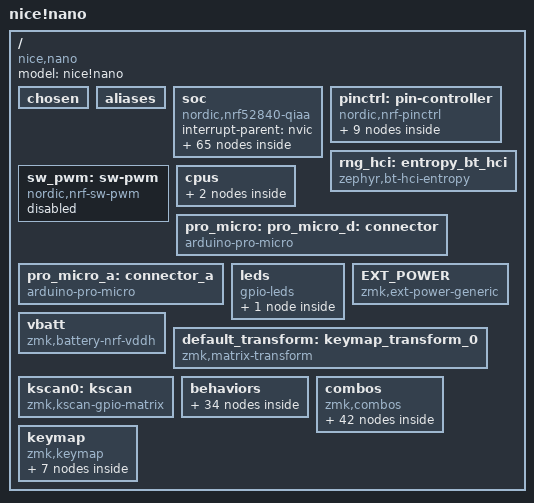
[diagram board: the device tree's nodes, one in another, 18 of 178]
/dts-v1/;

/ {
	#address-cells = < 0x1 >;
	#size-cells = < 0x1 >;
	model = "nice!nano";
	compatible = "nice,nano";
	chosen {
		zephyr,entropy = &rng;
		zephyr,flash-controller = &flash_controller;
		zephyr,code-partition = &code_partition;
		zephyr,sram = &sram0;
		zephyr,flash = &flash0;
		zephyr,console = &cdc_acm_uart;
		zmk,battery = &vbatt;
		zmk,matrix-transform = &default_transform;
		zmk,kscan = &kscan0;
	};
	aliases {
	};
	soc {
		#address-cells = < 0x1 >;
		#size-cells = < 0x1 >;
		compatible = "nordic,nrf52840-qiaa", "nordic,nrf52840", "nordic,nrf52", "simple-bus";
		interrupt-parent = < &nvic >;
		ranges;
		nvic: interrupt-controller@e000e100 {
			#address-cells = < 0x1 >;
			compatible = "arm,v7m-nvic";
			reg = < 0xe000e100 0xc00 >;
			interrupt-controller;
			#interrupt-cells = < 0x2 >;
			arm,num-irq-priority-bits = < 0x3 >;
			phandle = < 0x1 >;
		};
		systick: timer@e000e010 {
			compatible = "arm,armv7m-systick";
			reg = < 0xe000e010 0x10 >;
			status = "disabled";
		};
		ficr: ficr@10000000 {
			compatible = "nordic,nrf-ficr";
			reg = < 0x10000000 0x1000 >;
			status = "okay";
		};
		uicr: uicr@10001000 {
			compatible = "nordic,nrf-uicr";
			reg = < 0x10001000 0x1000 >;
			status = "okay";
		};
		sram0: memory@20000000 {
			compatible = "mmio-sram";
			reg = < 0x20000000 0x40000 >;
		};
		clock: clock@40000000 {
			compatible = "nordic,nrf-clock";
			reg = < 0x40000000 0x1000 >;
			interrupts = < 0x0 0x1 >;
			status = "okay";
		};
		power: power@40000000 {
			compatible = "nordic,nrf-power";
			reg = < 0x40000000 0x1000 >;
			interrupts = < 0x0 0x1 >;
			status = "okay";
			#address-cells = < 0x1 >;
			#size-cells = < 0x1 >;
			gpregret1: gpregret1@4000051c {
				#address-cells = < 0x1 >;
				#size-cells = < 0x1 >;
				compatible = "nordic,nrf-gpregret";
				reg = < 0x4000051c 0x1 >;
				status = "okay";
			};
			gpregret2: gpregret2@40000520 {
				#address-cells = < 0x1 >;
				#size-cells = < 0x1 >;
				compatible = "nordic,nrf-gpregret";
				reg = < 0x40000520 0x1 >;
				status = "okay";
			};
		};
		radio: radio@40001000 {
			compatible = "nordic,nrf-radio";
			reg = < 0x40001000 0x1000 >;
			interrupts = < 0x1 0x1 >;
			status = "okay";
			ieee802154-supported;
			ble-2mbps-supported;
			ble-coded-phy-supported;
			tx-high-power-supported;
			ieee802154: ieee802154 {
				compatible = "nordic,nrf-ieee802154";
				status = "disabled";
			};
		};
		uart0: pro_micro_serial: uart@40002000 {
			compatible = "nordic,nrf-uarte";
			reg = < 0x40002000 0x1000 >;
			interrupts = < 0x2 0x1 >;
			status = "disabled";
			current-speed = < 0x1c200 >;
			pinctrl-0 = < &uart0_default >;
			pinctrl-1 = < &uart0_sleep >;
			pinctrl-names = "default", "sleep";
		};
		i2c0: pro_micro_i2c: i2c@40003000 {
			compatible = "nordic,nrf-twi";
			#address-cells = < 0x1 >;
			#size-cells = < 0x0 >;
			reg = < 0x40003000 0x1000 >;
			clock-frequency = < 0x186a0 >;
			interrupts = < 0x3 0x1 >;
			easydma-maxcnt-bits = < 0x10 >;
			status = "disabled";
			pinctrl-0 = < &i2c0_default >;
			pinctrl-1 = < &i2c0_sleep >;
			pinctrl-names = "default", "sleep";
		};
		spi0: pro_micro_spi: spi@40003000 {
			compatible = "nordic,nrf-spim";
			#address-cells = < 0x1 >;
			#size-cells = < 0x0 >;
			reg = < 0x40003000 0x1000 >;
			interrupts = < 0x3 0x1 >;
			max-frequency = < 0x7a1200 >;
			easydma-maxcnt-bits = < 0x10 >;
			status = "disabled";
		};
		i2c1: i2c@40004000 {
			compatible = "nordic,nrf-twim";
			#address-cells = < 0x1 >;
			#size-cells = < 0x0 >;
			reg = < 0x40004000 0x1000 >;
			clock-frequency = < 0x186a0 >;
			interrupts = < 0x4 0x1 >;
			easydma-maxcnt-bits = < 0x10 >;
			status = "disabled";
		};
		spi1: spi@40004000 {
			compatible = "nordic,nrf-spim";
			#address-cells = < 0x1 >;
			#size-cells = < 0x0 >;
			reg = < 0x40004000 0x1000 >;
			interrupts = < 0x4 0x1 >;
			max-frequency = < 0x7a1200 >;
			easydma-maxcnt-bits = < 0x10 >;
			status = "disabled";
		};
		nfct: nfct@40005000 {
			compatible = "nordic,nrf-nfct";
			reg = < 0x40005000 0x1000 >;
			interrupts = < 0x5 0x1 >;
			status = "okay";
		};
		gpiote: gpiote@40006000 {
			compatible = "nordic,nrf-gpiote";
			reg = < 0x40006000 0x1000 >;
			interrupts = < 0x6 0x5 >;
			status = "okay";
		};
		adc: adc@40007000 {
			compatible = "nordic,nrf-saadc";
			reg = < 0x40007000 0x1000 >;
			interrupts = < 0x7 0x1 >;
			status = "okay";
			#io-channel-cells = < 0x1 >;
		};
		timer0: timer@40008000 {
			compatible = "nordic,nrf-timer";
			status = "disabled";
			reg = < 0x40008000 0x1000 >;
			cc-num = < 0x4 >;
			max-bit-width = < 0x20 >;
			interrupts = < 0x8 0x1 >;
			prescaler = < 0x0 >;
		};
		timer1: timer@40009000 {
			compatible = "nordic,nrf-timer";
			status = "disabled";
			reg = < 0x40009000 0x1000 >;
			cc-num = < 0x4 >;
			max-bit-width = < 0x20 >;
			interrupts = < 0x9 0x1 >;
			prescaler = < 0x0 >;
			phandle = < 0x6 >;
		};
		timer2: timer@4000a000 {
			compatible = "nordic,nrf-timer";
			status = "disabled";
			reg = < 0x4000a000 0x1000 >;
			cc-num = < 0x4 >;
			max-bit-width = < 0x20 >;
			interrupts = < 0xa 0x1 >;
			prescaler = < 0x0 >;
		};
		rtc0: rtc@4000b000 {
			compatible = "nordic,nrf-rtc";
			reg = < 0x4000b000 0x1000 >;
			cc-num = < 0x3 >;
			interrupts = < 0xb 0x1 >;
			status = "disabled";
			clock-frequency = < 0x8000 >;
			prescaler = < 0x1 >;
		};
		temp: temp@4000c000 {
			compatible = "nordic,nrf-temp";
			reg = < 0x4000c000 0x1000 >;
			interrupts = < 0xc 0x1 >;
			status = "okay";
		};
		rng: random@4000d000 {
			compatible = "nordic,nrf-rng";
			reg = < 0x4000d000 0x1000 >;
			interrupts = < 0xd 0x1 >;
			status = "okay";
		};
		ecb: ecb@4000e000 {
			compatible = "nordic,nrf-ecb";
			reg = < 0x4000e000 0x1000 >;
			interrupts = < 0xe 0x1 >;
			status = "okay";
		};
		ccm: ccm@4000f000 {
			compatible = "nordic,nrf-ccm";
			reg = < 0x4000f000 0x1000 >;
			interrupts = < 0xf 0x1 >;
			length-field-length-8-bits;
			status = "okay";
		};
		wdt: wdt0: watchdog@40010000 {
			compatible = "nordic,nrf-wdt";
			reg = < 0x40010000 0x1000 >;
			interrupts = < 0x10 0x1 >;
			status = "okay";
		};
		rtc1: rtc@40011000 {
			compatible = "nordic,nrf-rtc";
			reg = < 0x40011000 0x1000 >;
			cc-num = < 0x4 >;
			interrupts = < 0x11 0x1 >;
			status = "disabled";
			clock-frequency = < 0x8000 >;
			prescaler = < 0x1 >;
		};
		qdec: qdec0: qdec@40012000 {
			compatible = "nordic,nrf-qdec";
			reg = < 0x40012000 0x1000 >;
			interrupts = < 0x12 0x1 >;
			status = "disabled";
		};
		comp: comparator@40013000 {
			compatible = "nordic,nrf-comp";
			reg = < 0x40013000 0x1000 >;
			interrupts = < 0x13 0x1 >;
			status = "disabled";
			#io-channel-cells = < 0x1 >;
		};
		egu0: swi0: egu@40014000 {
			compatible = "nordic,nrf-egu", "nordic,nrf-swi";
			reg = < 0x40014000 0x1000 >;
			interrupts = < 0x14 0x1 >;
			status = "okay";
		};
		egu1: swi1: egu@40015000 {
			compatible = "nordic,nrf-egu", "nordic,nrf-swi";
			reg = < 0x40015000 0x1000 >;
			interrupts = < 0x15 0x1 >;
			status = "okay";
		};
		egu2: swi2: egu@40016000 {
			compatible = "nordic,nrf-egu", "nordic,nrf-swi";
			reg = < 0x40016000 0x1000 >;
			interrupts = < 0x16 0x1 >;
			status = "okay";
		};
		egu3: swi3: egu@40017000 {
			compatible = "nordic,nrf-egu", "nordic,nrf-swi";
			reg = < 0x40017000 0x1000 >;
			interrupts = < 0x17 0x1 >;
			status = "okay";
		};
		egu4: swi4: egu@40018000 {
			compatible = "nordic,nrf-egu", "nordic,nrf-swi";
			reg = < 0x40018000 0x1000 >;
			interrupts = < 0x18 0x1 >;
			status = "okay";
		};
		egu5: swi5: egu@40019000 {
			compatible = "nordic,nrf-egu", "nordic,nrf-swi";
			reg = < 0x40019000 0x1000 >;
			interrupts = < 0x19 0x1 >;
			status = "okay";
		};
		timer3: timer@4001a000 {
			compatible = "nordic,nrf-timer";
			status = "disabled";
			reg = < 0x4001a000 0x1000 >;
			cc-num = < 0x6 >;
			max-bit-width = < 0x20 >;
			interrupts = < 0x1a 0x1 >;
			prescaler = < 0x0 >;
		};
		timer4: timer@4001b000 {
			compatible = "nordic,nrf-timer";
			status = "disabled";
			reg = < 0x4001b000 0x1000 >;
			cc-num = < 0x6 >;
			max-bit-width = < 0x20 >;
			interrupts = < 0x1b 0x1 >;
			prescaler = < 0x0 >;
		};
		pwm0: pwm@4001c000 {
			compatible = "nordic,nrf-pwm";
			reg = < 0x4001c000 0x1000 >;
			interrupts = < 0x1c 0x1 >;
			status = "disabled";
			#pwm-cells = < 0x3 >;
		};
		pdm0: pdm@4001d000 {
			compatible = "nordic,nrf-pdm";
			reg = < 0x4001d000 0x1000 >;
			interrupts = < 0x1d 0x1 >;
			status = "disabled";
		};
		acl: acl@4001e000 {
			compatible = "nordic,nrf-acl";
			reg = < 0x4001e000 0x1000 >;
			status = "okay";
		};
		flash_controller: flash-controller@4001e000 {
			compatible = "nordic,nrf52-flash-controller";
			reg = < 0x4001e000 0x1000 >;
			partial-erase;
			#address-cells = < 0x1 >;
			#size-cells = < 0x1 >;
			flash0: flash@0 {
				compatible = "soc-nv-flash";
				erase-block-size = < 0x1000 >;
				write-block-size = < 0x4 >;
				reg = < 0x0 0x100000 >;
				partitions {
					compatible = "fixed-partitions";
					#address-cells = < 0x1 >;
					#size-cells = < 0x1 >;
					sd_partition: partition@0 {
						reg = < 0x0 0x26000 >;
					};
					code_partition: partition@26000 {
						reg = < 0x26000 0xc6000 >;
					};
					storage_partition: partition@ec000 {
						reg = < 0xec000 0x8000 >;
					};
					boot_partition: partition@f4000 {
						reg = < 0xf4000 0xc000 >;
					};
				};
			};
		};
		ppi: ppi@4001f000 {
			compatible = "nordic,nrf-ppi";
			reg = < 0x4001f000 0x1000 >;
			status = "okay";
		};
		mwu: mwu@40020000 {
			compatible = "nordic,nrf-mwu";
			reg = < 0x40020000 0x1000 >;
			status = "okay";
		};
		pwm1: pwm@40021000 {
			compatible = "nordic,nrf-pwm";
			reg = < 0x40021000 0x1000 >;
			interrupts = < 0x21 0x1 >;
			status = "disabled";
			#pwm-cells = < 0x3 >;
		};
		pwm2: pwm@40022000 {
			compatible = "nordic,nrf-pwm";
			reg = < 0x40022000 0x1000 >;
			interrupts = < 0x22 0x1 >;
			status = "disabled";
			#pwm-cells = < 0x3 >;
		};
		spi2: spi@40023000 {
			compatible = "nordic,nrf-spim";
			#address-cells = < 0x1 >;
			#size-cells = < 0x0 >;
			reg = < 0x40023000 0x1000 >;
			interrupts = < 0x23 0x1 >;
			max-frequency = < 0x7a1200 >;
			easydma-maxcnt-bits = < 0x10 >;
			status = "disabled";
		};
		rtc2: rtc@40024000 {
			compatible = "nordic,nrf-rtc";
			reg = < 0x40024000 0x1000 >;
			cc-num = < 0x4 >;
			interrupts = < 0x24 0x1 >;
			status = "disabled";
			clock-frequency = < 0x8000 >;
			prescaler = < 0x1 >;
		};
		i2s0: i2s@40025000 {
			compatible = "nordic,nrf-i2s";
			#address-cells = < 0x1 >;
			#size-cells = < 0x0 >;
			reg = < 0x40025000 0x1000 >;
			interrupts = < 0x25 0x1 >;
			status = "disabled";
		};
		usbd: usbd@40027000 {
			compatible = "nordic,nrf-usbd";
			reg = < 0x40027000 0x1000 >;
			interrupts = < 0x27 0x1 >;
			num-bidir-endpoints = < 0x1 >;
			num-in-endpoints = < 0x7 >;
			num-out-endpoints = < 0x7 >;
			num-isoin-endpoints = < 0x1 >;
			num-isoout-endpoints = < 0x1 >;
			status = "okay";
			cdc_acm_uart: cdc_acm_uart {
				compatible = "zephyr,cdc-acm-uart";
			};
		};
		uart1: uart@40028000 {
			compatible = "nordic,nrf-uarte";
			reg = < 0x40028000 0x1000 >;
			interrupts = < 0x28 0x1 >;
			status = "disabled";
		};
		qspi: qspi@40029000 {
			compatible = "nordic,nrf-qspi";
			#address-cells = < 0x1 >;
			#size-cells = < 0x0 >;
			reg = < 0x40029000 0x1000 >, < 0x12000000 0x8000000 >;
			reg-names = "qspi", "qspi_mm";
			interrupts = < 0x29 0x1 >;
			status = "disabled";
		};
		pwm3: pwm@4002d000 {
			compatible = "nordic,nrf-pwm";
			reg = < 0x4002d000 0x1000 >;
			interrupts = < 0x2d 0x1 >;
			status = "disabled";
			#pwm-cells = < 0x3 >;
		};
		spi3: spi@4002f000 {
			compatible = "nordic,nrf-spim";
			#address-cells = < 0x1 >;
			#size-cells = < 0x0 >;
			reg = < 0x4002f000 0x1000 >;
			interrupts = < 0x2f 0x1 >;
			max-frequency = < 0x1e84800 >;
			easydma-maxcnt-bits = < 0x10 >;
			rx-delay-supported;
			rx-delay = < 0x2 >;
			status = "disabled";
		};
		gpio0: gpio@50000000 {
			compatible = "nordic,nrf-gpio";
			gpio-controller;
			reg = < 0x50000000 0x200 0x50000500 0x300 >;
			#gpio-cells = < 0x2 >;
			status = "okay";
			port = < 0x0 >;
			phandle = < 0x7 >;
		};
		gpio1: gpio@50000300 {
			compatible = "nordic,nrf-gpio";
			gpio-controller;
			reg = < 0x50000300 0x200 0x50000800 0x300 >;
			#gpio-cells = < 0x2 >;
			ngpios = < 0x10 >;
			status = "okay";
			port = < 0x1 >;
			phandle = < 0x8 >;
		};
		cryptocell: crypto@5002a000 {
			compatible = "nordic,cryptocell", "arm,cryptocell-310";
			reg = < 0x5002a000 0x1000 >, < 0x5002b000 0x1000 >;
			reg-names = "wrapper", "core";
			interrupts = < 0x2a 0x1 >;
			status = "disabled";
		};
	};
	pinctrl: pin-controller {
		compatible = "nordic,nrf-pinctrl";
		uart0_default: uart0_default {
			phandle = < 0x2 >;
			group1 {
				psels = < 0x10008 >;
				bias-pull-up;
			};
			group2 {
				psels = < 0x6 >;
			};
		};
		uart0_sleep: uart0_sleep {
			phandle = < 0x3 >;
			group1 {
				psels = < 0x10008 >, < 0x6 >;
				low-power-enable;
			};
		};
		i2c0_default: i2c0_default {
			phandle = < 0x4 >;
			group1 {
				psels = < 0xc0011 >, < 0xb0014 >;
			};
		};
		i2c0_sleep: i2c0_sleep {
			phandle = < 0x5 >;
			group1 {
				psels = < 0xc0011 >, < 0xb0014 >;
				low-power-enable;
			};
		};
	};
	rng_hci: entropy_bt_hci {
		compatible = "zephyr,bt-hci-entropy";
		status = "okay";
	};
	sw_pwm: sw-pwm {
		compatible = "nordic,nrf-sw-pwm";
		status = "disabled";
		generator = < &timer1 >;
		clock-prescaler = < 0x0 >;
		#pwm-cells = < 0x3 >;
	};
	cpus {
		#address-cells = < 0x1 >;
		#size-cells = < 0x0 >;
		cpu@0 {
			device_type = "cpu";
			compatible = "arm,cortex-m4f";
			reg = < 0x0 >;
			#address-cells = < 0x1 >;
			#size-cells = < 0x1 >;
			itm: itm@e0000000 {
				compatible = "arm,armv7m-itm";
				reg = < 0xe0000000 0x1000 >;
				swo-ref-frequency = < 0x1e84800 >;
			};
		};
	};
	pro_micro: pro_micro_d: connector {
		compatible = "arduino-pro-micro";
		#gpio-cells = < 0x2 >;
		gpio-map-mask = < 0xffffffff 0xffffffc0 >;
		gpio-map-pass-thru = < 0x0 0x3f >;
		gpio-map = < 0x0 0x0 &gpio0 0x8 0x0 >, < 0x1 0x0 &gpio0 0x6 0x0 >, < 0x2 0x0 &gpio0 0x11 0x0 >, < 0x3 0x0 &gpio0 0x14 0x0 >, < 0x4 0x0 &gpio0 0x16 0x0 >, < 0x5 0x0 &gpio0 0x18 0x0 >, < 0x6 0x0 &gpio1 0x0 0x0 >, < 0x7 0x0 &gpio0 0xb 0x0 >, < 0x8 0x0 &gpio1 0x4 0x0 >, < 0x9 0x0 &gpio1 0x6 0x0 >, < 0xa 0x0 &gpio0 0x9 0x0 >, < 0x10 0x0 &gpio0 0xa 0x0 >, < 0xe 0x0 &gpio1 0xb 0x0 >, < 0xf 0x0 &gpio1 0xd 0x0 >, < 0x12 0x0 &gpio1 0xf 0x0 >, < 0x13 0x0 &gpio0 0x2 0x0 >, < 0x14 0x0 &gpio0 0x1d 0x0 >, < 0x15 0x0 &gpio0 0x1f 0x0 >;
		phandle = < 0x9 >;
	};
	pro_micro_a: connector_a {
		compatible = "arduino-pro-micro";
		#gpio-cells = < 0x2 >;
		gpio-map-mask = < 0xffffffff 0xffffffc0 >;
		gpio-map-pass-thru = < 0x0 0x3f >;
		gpio-map = < 0x0 0x0 &gpio1 0xf 0x0 >, < 0x1 0x0 &gpio0 0x2 0x0 >, < 0x2 0x0 &gpio0 0x1d 0x0 >, < 0x3 0x0 &gpio0 0x1f 0x0 >, < 0x6 0x0 &gpio0 0x16 0x0 >, < 0x7 0x0 &gpio1 0x0 0x0 >, < 0x8 0x0 &gpio1 0x4 0x0 >, < 0x9 0x0 &gpio1 0x6 0x0 >, < 0xa 0x0 &gpio0 0x9 0x0 >;
	};
	leds {
		compatible = "gpio-leds";
		blue_led: led_0 {
			gpios = < &gpio0 0xf 0x0 >;
		};
	};
	EXT_POWER {
		compatible = "zmk,ext-power-generic";
		control-gpios = < &gpio0 0xd 0x0 >;
		init-delay-ms = < 0x32 >;
	};
	vbatt: vbatt {
		compatible = "zmk,battery-nrf-vddh";
	};
	default_transform: keymap_transform_0 {
		compatible = "zmk,matrix-transform";
		columns = < 0xa >;
		rows = < 0x4 >;
		map = < 0x0 0x1 0x2 0x3 0x4 0x5 0x6 0x7 0x8 0x9 0x100 0x101 0x102 0x103 0x104 0x105 0x106 0x107 0x108 0x109 0x200 0x201 0x202 0x203 0x204 0x205 0x206 0x207 0x208 0x209 0x303 0x304 0x305 0x306 0x307 0x308 >;
		col-offset = < 0x5 >;
	};
	kscan0: kscan {
		compatible = "zmk,kscan-gpio-matrix";
		diode-direction = "col2row";
		row-gpios = < &pro_micro 0x4 0x20 >, < &pro_micro 0x5 0x20 >, < &pro_micro 0x6 0x20 >, < &pro_micro 0x7 0x20 >;
		col-gpios = < &pro_micro 0xe 0x0 >, < &pro_micro 0xf 0x0 >, < &pro_micro 0x12 0x0 >, < &pro_micro 0x13 0x0 >, < &pro_micro 0x14 0x0 >;
	};
	behaviors {
		cp: kp: key_press {
			compatible = "zmk,behavior-key-press";
			#binding-cells = < 0x1 >;
			phandle = < 0xa >;
		};
		kt: key_toggle {
			compatible = "zmk,behavior-key-toggle";
			#binding-cells = < 0x1 >;
			phandle = < 0xd >;
		};
		trans: transparent {
			compatible = "zmk,behavior-transparent";
			#binding-cells = < 0x0 >;
			phandle = < 0x1a >;
		};
		sk: sticky_key {
			compatible = "zmk,behavior-sticky-key";
			#binding-cells = < 0x1 >;
			release-after-ms = < 0x7d0 >;
			bindings = < &kp >;
			ignore-modifiers;
			phandle = < 0xc >;
		};
		mo: momentary_layer {
			compatible = "zmk,behavior-momentary-layer";
			#binding-cells = < 0x1 >;
			phandle = < 0xb >;
		};
		tog: toggle_layer {
			compatible = "zmk,behavior-toggle-layer";
			#binding-cells = < 0x1 >;
			phandle = < 0xe >;
		};
		sys_reset: sysreset {
			compatible = "zmk,behavior-reset";
			#binding-cells = < 0x0 >;
		};
		bootloader: bootload {
			compatible = "zmk,behavior-reset";
			type = < 0x57 >;
			#binding-cells = < 0x0 >;
			phandle = < 0x12 >;
		};
		rgb_ug: rgb_ug {
			compatible = "zmk,behavior-rgb-underglow";
			#binding-cells = < 0x2 >;
		};
		bt: bluetooth {
			compatible = "zmk,behavior-bluetooth";
			#binding-cells = < 0x2 >;
			phandle = < 0x1f >;
		};
		ext_power: extpower {
			compatible = "zmk,behavior-ext-power";
			#binding-cells = < 0x1 >;
			phandle = < 0x10 >;
		};
		out: outputs {
			compatible = "zmk,behavior-outputs";
			#binding-cells = < 0x1 >;
			phandle = < 0x11 >;
		};
		macro_tap: macro_tap {
			compatible = "zmk,macro-control-mode-tap";
			#binding-cells = < 0x0 >;
		};
		macro_press: macro_press {
			compatible = "zmk,macro-control-mode-press";
			#binding-cells = < 0x0 >;
		};
		macro_release: macro_release {
			compatible = "zmk,macro-control-mode-release";
			#binding-cells = < 0x0 >;
		};
		macro_tap_time: macro_tap_time {
			compatible = "zmk,macro-control-tap-time";
			#binding-cells = < 0x1 >;
		};
		macro_wait_time: macro_wait_time {
			compatible = "zmk,macro-control-wait-time";
			#binding-cells = < 0x1 >;
		};
		macro_pause_for_release: macro_pause_for_release {
			compatible = "zmk,macro-pause-for-release";
			#binding-cells = < 0x0 >;
		};
		macro_param_1to1: macro_param_1to1 {
			compatible = "zmk,macro-param-1to1";
			#binding-cells = < 0x0 >;
		};
		macro_param_1to2: macro_param_1to2 {
			compatible = "zmk,macro-param-1to2";
			#binding-cells = < 0x0 >;
		};
		macro_param_2to1: macro_param_2to1 {
			compatible = "zmk,macro-param-2to1";
			#binding-cells = < 0x0 >;
		};
		macro_param_2to2: macro_param_2to2 {
			compatible = "zmk,macro-param-2to2";
			#binding-cells = < 0x0 >;
		};
		mkp: mouse_key_press {
			compatible = "zmk,behavior-mouse-key-press";
			#binding-cells = < 0x1 >;
			phandle = < 0xf >;
		};
		td_lshft: lshft_tap_dance {
			compatible = "zmk,behavior-tap-dance";
			#binding-cells = < 0x0 >;
			tapping-term-ms = < 0xc8 >;
			bindings = < &sk 0x700e1 >, < &kt 0x700e1 >;
			phandle = < 0x1b >;
		};
		td_lctrl: lctrl_tap_dance {
			compatible = "zmk,behavior-tap-dance";
			#binding-cells = < 0x0 >;
			tapping-term-ms = < 0xc8 >;
			bindings = < &sk 0x700e0 >, < &kt 0x700e0 >;
			phandle = < 0x1c >;
		};
		td_lgui: lgui_tap_dance {
			compatible = "zmk,behavior-tap-dance";
			#binding-cells = < 0x0 >;
			tapping-term-ms = < 0xc8 >;
			bindings = < &sk 0x700e1 >, < &kt 0x700e1 >;
			phandle = < 0x1d >;
		};
		td_lalt: lalt_tap_dance {
			compatible = "zmk,behavior-tap-dance";
			#binding-cells = < 0x0 >;
			tapping-term-ms = < 0xc8 >;
			bindings = < &sk 0x700e2 >, < &kt 0x700e2 >;
			phandle = < 0x1e >;
		};
		td_navmodlayer: navmod_layer_tap_dance {
			compatible = "zmk,behavior-tap-dance";
			#binding-cells = < 0x0 >;
			tapping-term-ms = < 0xc8 >;
			bindings = < &mo 0x1 >, < &tog 0x1 >;
			phandle = < 0x19 >;
		};
		td_seminav: seminav_tap_dance {
			compatible = "zmk,behavior-tap-dance";
			#binding-cells = < 0x0 >;
			tapping-term-ms = < 0xc8 >;
			bindings = < &kp 0x70033 >, < &mo 0x5 >, < &mo 0x6 >;
			phandle = < 0x18 >;
		};
		td_r_shifted: r_shifted_tap_dance {
			compatible = "zmk,behavior-tap-dance";
			#binding-cells = < 0x0 >;
			tapping-term-ms = < 0xc8 >;
			bindings = < &kp 0x70015 >, < &mo 0x3 >;
			phandle = < 0x14 >;
		};
		td_e_shifted: e_shifted_tap_dance {
			compatible = "zmk,behavior-tap-dance";
			#binding-cells = < 0x0 >;
			tapping-term-ms = < 0xc8 >;
			bindings = < &kp 0x70008 >, < &mo 0x3 >;
			phandle = < 0x13 >;
		};
		td_i_shifted: i_shifted_tap_dance {
			compatible = "zmk,behavior-tap-dance";
			#binding-cells = < 0x0 >;
			tapping-term-ms = < 0xc8 >;
			bindings = < &kp 0x7000c >, < &mo 0x3 >;
			phandle = < 0x16 >;
		};
		td_u_shifted: u_shifted_tap_dance {
			compatible = "zmk,behavior-tap-dance";
			#binding-cells = < 0x0 >;
			tapping-term-ms = < 0xc8 >;
			bindings = < &kp 0x70018 >, < &mo 0x3 >;
			phandle = < 0x15 >;
		};
		td_j_shifted: j_shifted_tap_dance {
			compatible = "zmk,behavior-tap-dance";
			#binding-cells = < 0x0 >;
			tapping-term-ms = < 0xc8 >;
			bindings = < &kp 0x7000d >, < &mo 0x3 >;
			phandle = < 0x17 >;
		};
	};
	combos {
		compatible = "zmk,combos";
		combo_grave {
			timeout-ms = < 0x14 >;
			key-positions = < 0x3 0x0 >;
			bindings = < &kp 0x70035 >;
		};
		combo_one {
			timeout-ms = < 0x14 >;
			key-positions = < 0x3 0xa >;
			bindings = < &kp 0x7001e >;
		};
		combo_two {
			timeout-ms = < 0x14 >;
			key-positions = < 0x3 0xb >;
			bindings = < &kp 0x7001f >;
		};
		combo_three {
			timeout-ms = < 0x14 >;
			key-positions = < 0x3 0xc >;
			bindings = < &kp 0x70020 >;
		};
		combo_four {
			timeout-ms = < 0x14 >;
			key-positions = < 0x2 0xd >;
			bindings = < &kp 0x70021 >;
		};
		combo_five {
			timeout-ms = < 0x14 >;
			key-positions = < 0x2 0xe >;
			bindings = < &kp 0x70022 >;
		};
		combo_six {
			timeout-ms = < 0x14 >;
			key-positions = < 0x7 0xf >;
			bindings = < &kp 0x70023 >;
		};
		combo_seven {
			timeout-ms = < 0x14 >;
			key-positions = < 0x7 0x10 >;
			bindings = < &kp 0x70024 >;
		};
		combo_eight {
			timeout-ms = < 0x14 >;
			key-positions = < 0x6 0x11 >;
			bindings = < &kp 0x70025 >;
		};
		combo_nine {
			timeout-ms = < 0x14 >;
			key-positions = < 0x6 0x12 >;
			bindings = < &kp 0x70026 >;
		};
		combo_zero {
			timeout-ms = < 0x14 >;
			key-positions = < 0x6 0x13 >;
			bindings = < &kp 0x70027 >;
		};
		combo_minus {
			timeout-ms = < 0x32 >;
			key-positions = < 0x10 0x1c >;
			bindings = < &kp 0x7002d >;
		};
		combo_equal {
			timeout-ms = < 0x32 >;
			key-positions = < 0x10 0x1d >;
			bindings = < &kp 0x7002e >;
		};
		combo_singe_quote {
			timeout-ms = < 0x14 >;
			key-positions = < 0x9 0x10 >;
			bindings = < &kp 0x70034 >;
		};
		combo_backslash {
			timeout-ms = < 0x14 >;
			key-positions = < 0x6 0x7 >;
			bindings = < &kp 0x70031 >;
		};
		combo_left_bracket {
			timeout-ms = < 0x14 >;
			key-positions = < 0x6 0x8 >;
			bindings = < &kp 0x7002f >;
		};
		combo_right_bracket {
			timeout-ms = < 0x14 >;
			key-positions = < 0x6 0x9 >;
			bindings = < &kp 0x70030 >;
		};
		combo_left {
			timeout-ms = < 0x14 >;
			key-positions = < 0x13 0xf >;
			bindings = < &kp 0x70050 >;
		};
		combo_down {
			timeout-ms = < 0x14 >;
			key-positions = < 0x13 0x10 >;
			bindings = < &kp 0x70051 >;
		};
		combo_up {
			timeout-ms = < 0x14 >;
			key-positions = < 0x13 0x11 >;
			bindings = < &kp 0x70052 >;
		};
		combo_right {
			timeout-ms = < 0x14 >;
			key-positions = < 0x13 0x12 >;
			bindings = < &kp 0x7004f >;
		};
		combo_home {
			timeout-ms = < 0x14 >;
			key-positions = < 0x13 0x19 >;
			bindings = < &kp 0x7004a >;
		};
		combo_page_down {
			timeout-ms = < 0x14 >;
			key-positions = < 0x13 0x1a >;
			bindings = < &kp 0x7004e >;
		};
		combo_page_up {
			timeout-ms = < 0x14 >;
			key-positions = < 0x13 0x1b >;
			bindings = < &kp 0x7004b >;
		};
		combo_end {
			timeout-ms = < 0x14 >;
			key-positions = < 0x13 0x1c >;
			bindings = < &kp 0x7004d >;
		};
		combo_escape {
			timeout-ms = < 0x14 >;
			key-positions = < 0x0 0x1 >;
			bindings = < &kp 0x70029 >;
		};
		combo_tab {
			timeout-ms = < 0x14 >;
			key-positions = < 0xa 0xb >;
			bindings = < &kp 0x7002b >;
		};
		combo_delete {
			timeout-ms = < 0x14 >;
			key-positions = < 0x7 0x8 >;
			bindings = < &kp 0x7004c >;
		};
		combo_lctrldelete {
			timeout-ms = < 0x14 >;
			key-positions = < 0x6 0x7 0x8 >;
			bindings = < &kp 0x107004c >;
		};
		combo_backspace {
			timeout-ms = < 0x14 >;
			key-positions = < 0x11 0x12 >;
			bindings = < &kp 0x7002a >;
		};
		combo_lctrlbackspace {
			timeout-ms = < 0x14 >;
			key-positions = < 0x10 0x11 0x12 >;
			bindings = < &kp 0x107002a >;
		};
		combo_enter {
			timeout-ms = < 0x14 >;
			key-positions = < 0x1b 0x1c >;
			bindings = < &kp 0x70028 >;
		};
		combo_printscreen {
			timeout-ms = < 0x14 >;
			key-positions = < 0x7 0x8 0x9 >;
			bindings = < &kp 0x70046 >;
		};
		combo_left_click {
			timeout-ms = < 0x14 >;
			key-positions = < 0x1 0x2 >;
			bindings = < &mkp 0x1 >;
		};
		combo_right_click {
			timeout-ms = < 0x14 >;
			key-positions = < 0x2 0x3 >;
			bindings = < &kp 0x2 >;
		};
		combo_middle_click {
			timeout-ms = < 0x14 >;
			key-positions = < 0x1 0x2 0x3 >;
			bindings = < &mkp 0x4 >;
		};
		combo_external_power_on {
			timeout-ms = < 0x14 >;
			key-positions = < 0x1e 0x1f 0x20 >;
			bindings = < &ext_power 0x1 >;
		};
		combo_external_power_off {
			timeout-ms = < 0x14 >;
			key-positions = < 0x1e 0x20 >;
			bindings = < &ext_power 0x0 >;
		};
		combo_output_bluetooth {
			timeout-ms = < 0x14 >;
			key-positions = < 0x0 0x4 >;
			bindings = < &out 0x2 >;
		};
		combo_output_usb {
			timeout-ms = < 0x14 >;
			key-positions = < 0xa 0xe >;
			bindings = < &out 0x1 >;
		};
		combo_sys_reset_left {
			timeout-ms = < 0x32 >;
			key-positions = < 0x14 0x18 >;
			bindings = < &bootloader >;
		};
		combo_sys_reset_right {
			timeout-ms = < 0x32 >;
			key-positions = < 0x19 0x1d >;
			bindings = < &bootloader >;
		};
	};
	keymap {
		compatible = "zmk,keymap";
		0 {
			bindings = < &kp 0x70014 &kp 0x7001a &td_e_shifted &td_r_shifted &kp 0x70017 &kp 0x7001c &td_u_shifted &td_i_shifted &kp 0x70012 &kp 0x70013 &kp 0x70004 &kp 0x70016 &kp 0x70007 &kp 0x70009 &kp 0x7000a &kp 0x7000b &td_j_shifted &kp 0x7000e &kp 0x7000f &td_seminav &kp 0x7001d &kp 0x7001b &kp 0x70006 &kp 0x70019 &kp 0x70005 &kp 0x70011 &kp 0x70010 &kp 0x70036 &kp 0x70037 &kp 0x70038 &kp 0x700e0 &kp 0x70065 &kp 0x700e1 &kp 0x7002c &td_navmodlayer &kp 0x700e6 >;
		};
		1 {
			bindings = < &trans &trans &trans &trans &trans &kp 0x700e8 &kp 0x70081 &kp 0x70080 &kp 0x7007f &trans &td_lshft &trans &trans &trans &trans &kp 0x70050 &kp 0x70051 &kp 0x70052 &kp 0x7004f &trans &td_lctrl &td_lgui &td_lalt &trans &trans &kp 0x7004a &kp 0x7004e &kp 0x7004b &kp 0x7004d &trans &mo 0x4 &mo 0x2 &trans &trans &trans &trans >;
		};
		2 {
			bindings = < &trans &trans &trans &trans &bt 0x0 0x0 &trans &trans &trans &trans &trans &bt 0x3 0x0 &bt 0x3 0x1 &bt 0x3 0x2 &bt 0x3 0x3 &bt 0x3 0x4 &trans &trans &trans &trans &trans &trans &trans &trans &trans &trans &trans &trans &trans &trans &trans &trans &trans &trans &trans &trans &trans >;
		};
		3 {
			bindings = < &kp 0x2070035 &trans &trans &trans &trans &trans &trans &kp 0x2070031 &kp 0x207002f &kp 0x2070030 &kp 0x207001e &kp 0x207001f &kp 0x2070020 &kp 0x2070021 &kp 0x2070022 &kp 0x2070023 &kp 0x2070024 &kp 0x2070025 &kp 0x2070026 &kp 0x2070027 &trans &trans &trans &trans &trans &trans &trans &trans &kp 0x207002d &kp 0x207002e &trans &trans &trans &trans &trans &trans >;
		};
		4 {
			bindings = < &kp 0x7003a &kp 0x7003b &kp 0x7003c &kp 0x7003d &kp 0x7003e &kp 0x7003f &kp 0x70040 &kp 0x70041 &kp 0x70042 &kp 0x70043 &td_lshft &trans &trans &trans &trans &trans &trans &trans &kp 0x70044 &kp 0x70045 &td_lctrl &td_lgui &td_lalt &trans &trans &trans &trans &trans &trans &trans &trans &trans &trans &trans &trans &trans >;
		};
		5 {
			bindings = < &trans &trans &trans &trans &trans &trans &trans &trans &trans &trans &td_lshft &trans &trans &trans &trans &kp 0x1070050 &kp 0x1070051 &kp 0x1070052 &kp 0x107004f &trans &td_lctrl &td_lgui &td_lalt &trans &trans &kp 0x107004a &kp 0x107004e &kp 0x107004b &kp 0x107004d &trans &trans &trans &trans &trans &trans &trans >;
		};
		6 {
			bindings = < &trans &trans &trans &trans &trans &trans &trans &trans &trans &trans &td_lshft &trans &trans &trans &trans &kp 0x3070050 &kp 0x3070051 &kp 0x3070052 &kp 0x307004f &trans &td_lctrl &td_lgui &td_lalt &trans &trans &kp 0x307004a &kp 0x307004e &kp 0x307004b &kp 0x307004d &trans &trans &trans &trans &trans &trans &trans >;
		};
	};
};
